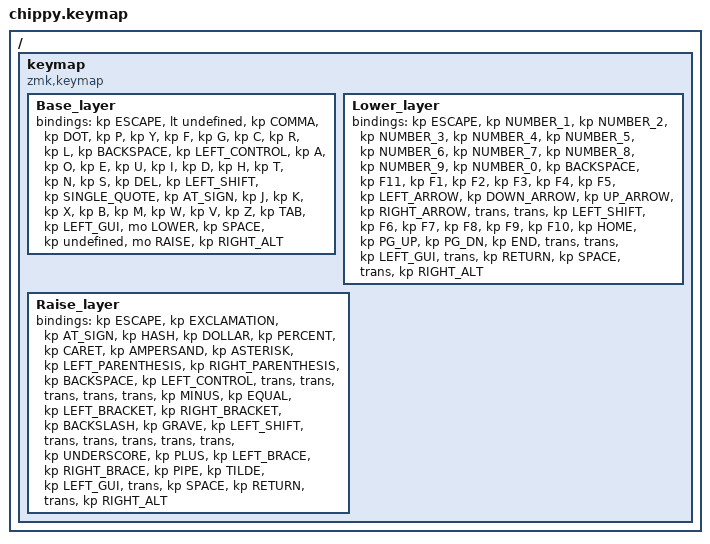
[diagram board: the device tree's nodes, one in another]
/*
*
* Copyright (c) 2021 Darryl deHaan
* SPDX-License-Identifier: MIT
*
*/

#include <behaviors.dtsi>
#include <dt-bindings/zmk/keys.h>
#include <dt-bindings/zmk/bt.h>
#include <dt-bindings/zmk/outputs.h>

#define BASE 0
#define LOWER 1
#define RAISE 2

/ {
  keymap {
    compatible = "zmk,keymap";

    Base_layer {
      bindings = <
        &kp ESCAPE &lt  undefined &kp COMMA &kp DOT &kp P &kp Y &kp F &kp G &kp C &kp R &kp L &kp BACKSPACE &kp LEFT_CONTROL &kp A &kp O &kp E &kp U &kp I &kp D &kp H &kp T &kp N &kp S &kp DEL &kp LEFT_SHIFT &kp SINGLE_QUOTE &kp AT_SIGN &kp J &kp K &kp X &kp B &kp M &kp W &kp V &kp Z &kp TAB &kp LEFT_GUI &mo LOWER &kp SPACE &kp undefined &mo RAISE &kp RIGHT_ALT 
      >;
    };

    Lower_layer {
      bindings = <
        &kp ESCAPE &kp NUMBER_1 &kp NUMBER_2 &kp NUMBER_3 &kp NUMBER_4 &kp NUMBER_5 &kp NUMBER_6 &kp NUMBER_7 &kp NUMBER_8 &kp NUMBER_9 &kp NUMBER_0 &kp BACKSPACE &kp F11 &kp F1 &kp F2 &kp F3 &kp F4 &kp F5 &kp LEFT_ARROW &kp DOWN_ARROW &kp UP_ARROW &kp RIGHT_ARROW &trans &trans &kp LEFT_SHIFT &kp F6 &kp F7 &kp F8 &kp F9 &kp F10 &kp HOME &kp PG_UP &kp PG_DN &kp END &trans &trans &kp LEFT_GUI &trans &kp RETURN &kp SPACE &trans &kp RIGHT_ALT 
      >;
    };

    Raise_layer {
      bindings = <
        &kp ESCAPE &kp EXCLAMATION &kp AT_SIGN &kp HASH &kp DOLLAR &kp PERCENT &kp CARET &kp AMPERSAND &kp ASTERISK &kp LEFT_PARENTHESIS &kp RIGHT_PARENTHESIS &kp BACKSPACE &kp LEFT_CONTROL &trans &trans &trans &trans &trans &kp MINUS &kp EQUAL &kp LEFT_BRACKET &kp RIGHT_BRACKET &kp BACKSLASH &kp GRAVE &kp LEFT_SHIFT &trans &trans &trans &trans &trans &kp UNDERSCORE &kp PLUS &kp LEFT_BRACE &kp RIGHT_BRACE &kp PIPE &kp TILDE &kp LEFT_GUI &trans &kp SPACE &kp RETURN &trans &kp RIGHT_ALT 
      >;
    };

  };
};
